VERSION ""

NS_ :

BS_:

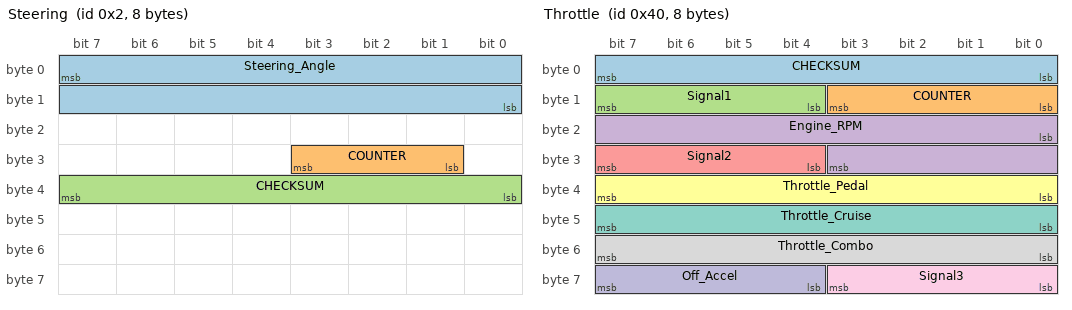
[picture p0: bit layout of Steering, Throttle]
BO_ 2 Steering: 8 XXX
 SG_ Steering_Angle : 7|16@0- (0.1,0) [0|65535] "" XXX
 SG_ COUNTER : 25|3@1+ (1,0) [0|7] "" XXX
 SG_ CHECKSUM : 32|8@1+ (1,0) [0|255] "" XXX

BO_ 64 Throttle: 8 XXX
 SG_ CHECKSUM : 0|8@1+ (1,0) [0|255] "" XXX
 SG_ COUNTER : 8|4@1+ (1,0) [0|15] "" XXX
 SG_ Signal1 : 12|4@1+ (1,0) [0|15] "" XXX
 SG_ Engine_RPM : 16|12@1+ (1,0) [0|4095] "" XXX
 SG_ Signal2 : 28|4@1+ (1,0) [0|15] "" XXX
 SG_ Throttle_Pedal : 32|8@1+ (1,0) [0|255] "" XXX
 SG_ Throttle_Cruise : 40|8@1+ (1,0) [0|255] "" XXX
 SG_ Throttle_Combo : 48|8@1+ (1,0) [0|255] "" XXX
 SG_ Signal3 : 56|4@1+ (1,0) [0|15] "" XXX
 SG_ Off_Accel : 60|4@1+ (1,0) [0|15] "" XXX

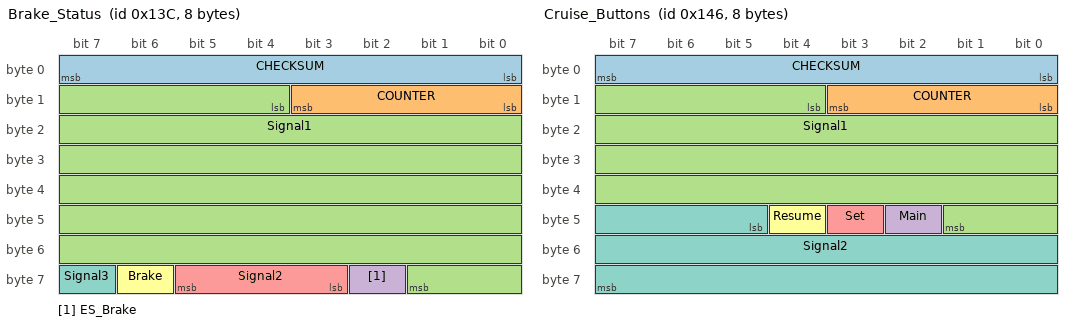
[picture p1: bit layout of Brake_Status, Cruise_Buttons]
BO_ 316 Brake_Status: 8 XXX
 SG_ CHECKSUM : 0|8@1+ (1,0) [0|255] "" XXX
 SG_ COUNTER : 8|4@1+ (1,0) [0|15] "" XXX
 SG_ Signal1 : 12|46@1+ (1,0) [0|1] "" XXX
 SG_ ES_Brake : 58|1@1+ (1,0) [0|1] "" XXX
 SG_ Signal2 : 59|3@1+ (1,0) [0|1] "" XXX
 SG_ Brake : 62|1@1+ (1,0) [0|1] "" XXX
 SG_ Signal3 : 63|1@1+ (1,0) [0|1] "" XXX

BO_ 326 Cruise_Buttons: 8 XXX
 SG_ CHECKSUM : 0|8@1+ (1,0) [0|255] "" XXX
 SG_ COUNTER : 8|4@1+ (1,0) [0|15] "" XXX
 SG_ Signal1 : 12|30@1+ (1,0) [0|1073741823] "" XXX
 SG_ Main : 42|1@1+ (1,0) [0|1] "" XXX
 SG_ Set : 43|1@1+ (1,0) [0|1] "" XXX
 SG_ Resume : 44|1@1+ (1,0) [0|1] "" XXX
 SG_ Signal2 : 45|19@1+ (1,0) [0|524287] "" XXX

BO_ 315 G_Sensor: 8 XXX
 SG_ Lateral : 48|8@1- (-0.1,0) [0|255] "m/s2" XXX
 SG_ Longitudinal : 56|8@1- (-0.1,0) [0|255] "m/s2" XXX

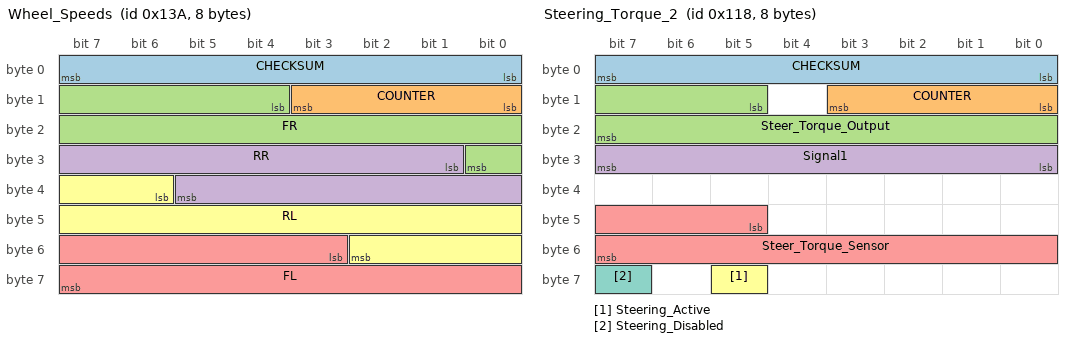
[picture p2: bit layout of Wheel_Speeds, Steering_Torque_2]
BO_ 314 Wheel_Speeds: 8 XXX
 SG_ CHECKSUM : 0|8@1+ (1,0) [0|255] "" XXX
 SG_ COUNTER : 8|4@1+ (1,0) [0|15] "" XXX
 SG_ FR : 12|13@1+ (0.057,0) [0|255] "kph" XXX
 SG_ RR : 25|13@1+ (0.057,0) [0|255] "kph" XXX
 SG_ FL : 51|13@1+ (0.057,0) [0|255] "kph" XXX
 SG_ RL : 38|13@1+ (0.057,0) [0|255] "kph" XXX

BO_ 280 Steering_Torque_2: 8 XXX
 SG_ CHECKSUM : 0|8@1+ (1,0) [0|255] "" XXX
 SG_ COUNTER : 8|4@1+ (1,0) [0|15] "" XXX
 SG_ Steer_Torque_Output : 13|11@1- (-10,0) [0|255] "" XXX
 SG_ Signal1 : 24|8@1+ (1,0) [0|511] "" XXX
 SG_ Steer_Torque_Sensor : 45|11@1- (-1,0) [0|255] "" XXX
 SG_ Steering_Active : 61|1@0+ (1,0) [0|1] "" XXX
 SG_ Steering_Disabled : 63|1@1+ (1,0) [0|1] "" XXX

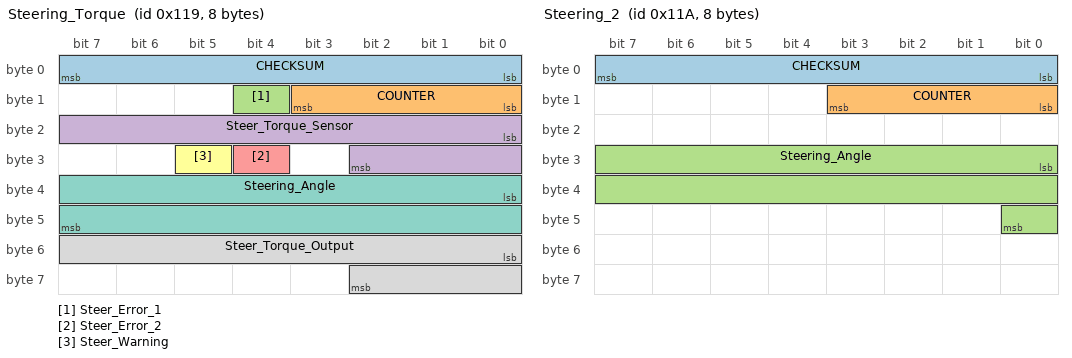
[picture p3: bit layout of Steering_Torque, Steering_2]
BO_ 281 Steering_Torque: 8 XXX
 SG_ CHECKSUM : 0|8@1+ (1,0) [0|255] "" XXX
 SG_ COUNTER : 8|4@1+ (1,0) [0|15] "" XXX
 SG_ Steer_Error_1 : 12|1@0+ (1,0) [0|1] "" XXX
 SG_ Steer_Torque_Sensor : 16|11@1- (-1,0) [-1000|1000] "" XXX
 SG_ Steer_Error_2 : 28|1@1+ (1,0) [0|1] "" XXX
 SG_ Steer_Warning : 29|1@1+ (1,0) [0|1] "" XXX
 SG_ Steering_Angle : 32|16@1- (-0.0217,0) [-600|600] "" X
 SG_ Steer_Torque_Output : 48|11@1- (-10,0) [-1000|1000] "" XXX

BO_ 282 Steering_2: 8 XXX
 SG_ CHECKSUM : 0|8@1+ (1,0) [0|1] "" XXX
 SG_ COUNTER : 8|4@1+ (1,0) [0|1] "" XXX
 SG_ Steering_Angle : 24|17@1- (-0.01,0) [0|1] "" XXX

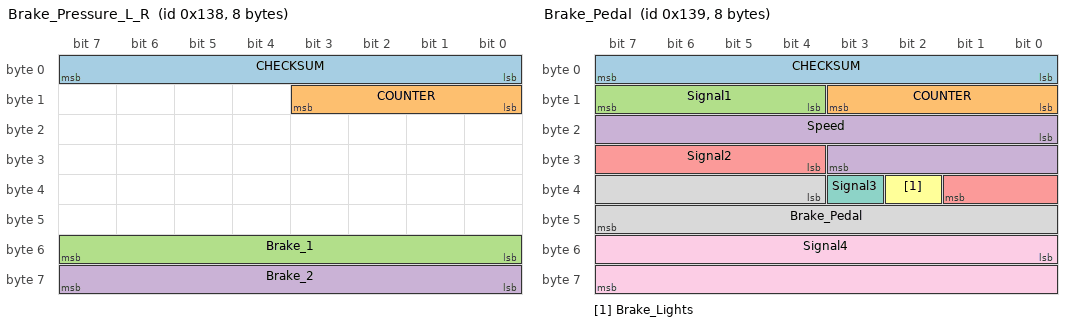
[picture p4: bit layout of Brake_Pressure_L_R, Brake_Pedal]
BO_ 312 Brake_Pressure_L_R: 8 XXX
 SG_ CHECKSUM : 0|8@1+ (1,0) [0|255] "" XXX
 SG_ COUNTER : 8|4@1+ (1,0) [0|15] "" XXX
 SG_ Brake_1 : 48|8@1+ (1,0) [0|255] "" XXX
 SG_ Brake_2 : 56|8@1+ (1,0) [0|255] "" XXX

BO_ 313 Brake_Pedal: 8 XXX
 SG_ CHECKSUM : 0|8@1+ (1,0) [0|255] "" XXX
 SG_ COUNTER : 8|4@1+ (1,0) [0|15] "" XXX
 SG_ Signal1 : 12|4@1+ (1,0) [0|15] "" XXX
 SG_ Speed : 16|12@1+ (0.05625,0) [0|255] "kph" XXX
 SG_ Signal2 : 28|6@1+ (1,0) [0|63] "" XXX
 SG_ Brake_Lights : 34|1@1+ (1,0) [0|1] "" XXX
 SG_ Signal3 : 35|1@1+ (1,0) [0|1] "" XXX
 SG_ Brake_Pedal : 36|12@1+ (1,0) [0|4095] "" XXX
 SG_ Signal4 : 48|16@1+ (1,0) [0|65535] "" XXX

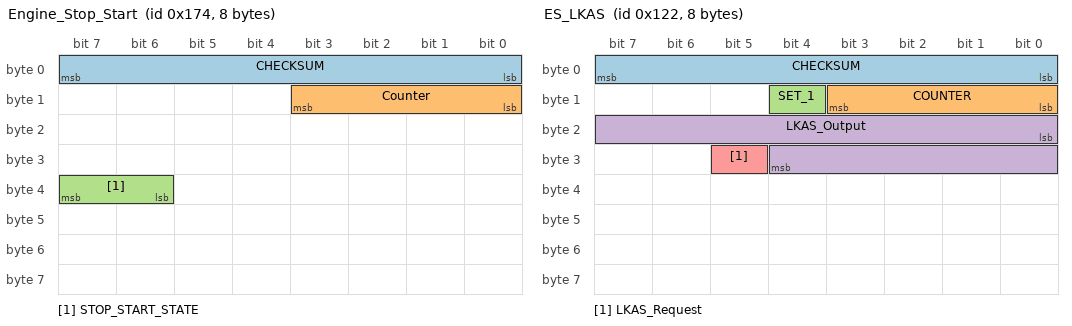
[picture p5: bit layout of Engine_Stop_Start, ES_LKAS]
BO_ 372 Engine_Stop_Start: 8 XXX
 SG_ CHECKSUM : 0|8@1+ (1,0) [0|255] "" XXX
 SG_ Counter : 8|4@1+ (1,0) [0|15] "" XXX
 SG_ STOP_START_STATE : 39|2@0+ (1,0) [0|3] "" XXX

BO_ 290 ES_LKAS: 8 XXX
 SG_ CHECKSUM : 0|8@1+ (1,0) [0|255] "" XXX
 SG_ COUNTER : 8|4@1+ (1,0) [0|15] "" XXX
 SG_ SET_1 : 12|1@0+ (1,0) [0|1] "" XXX
 SG_ LKAS_Output : 16|13@1- (-1,0) [-8191|8191] "" XXX
 SG_ LKAS_Request : 29|1@0+ (1,0) [0|1] "" XXX

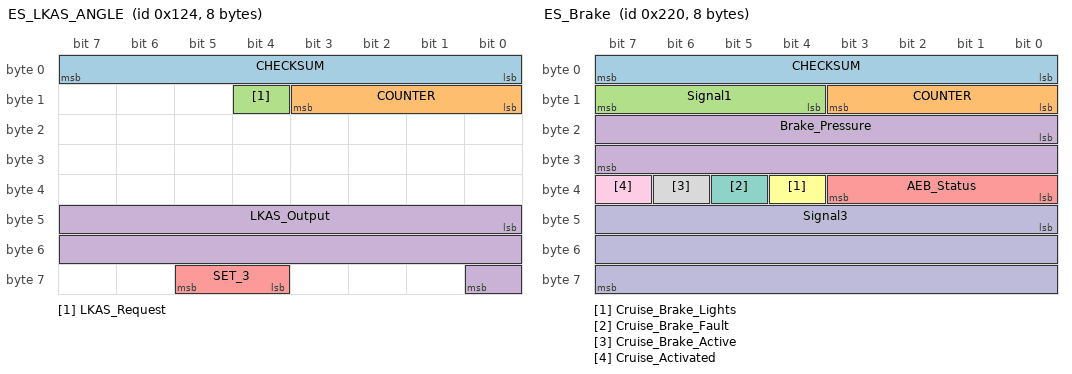
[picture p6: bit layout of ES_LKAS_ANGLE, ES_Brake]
BO_ 292 ES_LKAS_ANGLE: 8 XXX
 SG_ CHECKSUM : 0|8@1+ (1,0) [0|1] "" XXX
 SG_ COUNTER : 8|4@1+ (1,0) [0|1] "" XXX
 SG_ LKAS_Request : 12|1@1+ (1,0) [0|1] "" XXX
 SG_ LKAS_Output : 40|17@1- (-0.01,0) [0|1] "deg" XXX
 SG_ SET_3 : 60|2@1+ (1,0) [0|1] "" XXX

BO_ 544 ES_Brake: 8 XXX
 SG_ CHECKSUM : 0|8@1+ (1,0) [0|255] "" XXX
 SG_ COUNTER : 8|4@1+ (1,0) [0|15] "" XXX
 SG_ Signal1 : 12|4@1+ (1,0) [0|15] "" XXX
 SG_ Brake_Pressure : 16|16@1+ (1,0) [0|65535] "" XXX
 SG_ AEB_Status : 32|4@1+ (1,0) [0|15] "" XXX
 SG_ Cruise_Brake_Lights : 36|1@1+ (1,0) [0|1] "" XXX
 SG_ Cruise_Brake_Fault : 37|1@1+ (1,0) [0|1] "" XXX
 SG_ Cruise_Brake_Active : 38|1@1+ (1,0) [0|1] "" XXX
 SG_ Cruise_Activated : 39|1@1+ (1,0) [0|1] "" XXX
 SG_ Signal3 : 40|24@1+ (1,0) [0|16777215] "" XXX

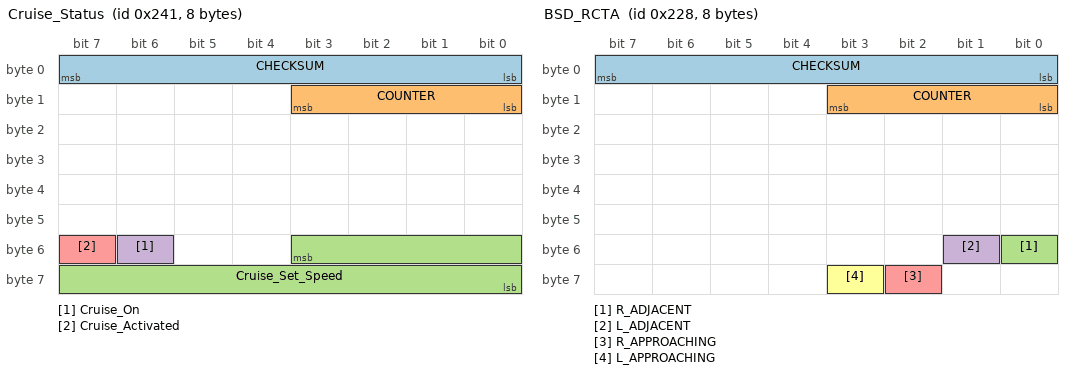
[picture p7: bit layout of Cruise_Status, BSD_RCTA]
BO_ 577 Cruise_Status: 8 XXX
 SG_ CHECKSUM : 0|8@1+ (1,0) [0|255] "" XXX
 SG_ COUNTER : 8|4@1+ (1,0) [0|15] "" XXX
 SG_ Cruise_Set_Speed : 51|12@0+ (1,0) [0|120] "" XXX
 SG_ Cruise_On : 54|1@1+ (1,0) [0|1] "" XXX
 SG_ Cruise_Activated : 55|1@1+ (1,0) [0|1] "" XXX

BO_ 552 BSD_RCTA: 8 XXX
 SG_ CHECKSUM : 0|8@1+ (1,0) [0|255] "" XXX
 SG_ COUNTER : 8|4@1+ (1,0) [0|15] "" XXX
 SG_ R_ADJACENT : 48|1@1+ (1,0) [0|1] "" XXX
 SG_ L_ADJACENT : 49|1@1+ (1,0) [0|1] "" XXX
 SG_ R_APPROACHING : 58|1@1+ (1,0) [0|1] "" XXX
 SG_ L_APPROACHING : 59|1@1+ (1,0) [0|1] "" XXX

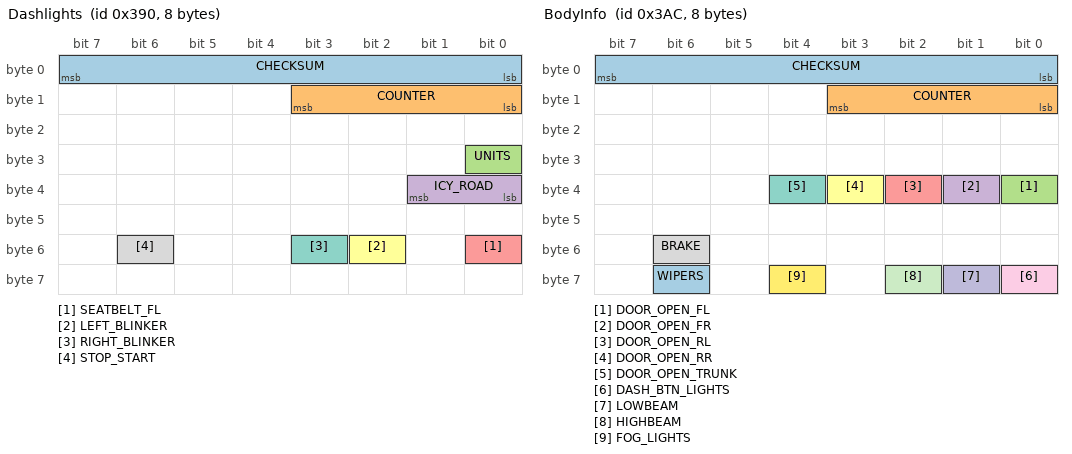
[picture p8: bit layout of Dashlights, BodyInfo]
BO_ 912 Dashlights: 8 XXX
 SG_ CHECKSUM : 0|8@1+ (1,0) [0|255] "" XXX
 SG_ COUNTER : 8|4@1+ (1,0) [0|15] "" XXX
 SG_ UNITS : 24|1@1+ (1,0) [0|1] "" XXX
 SG_ ICY_ROAD : 32|2@1+ (1,0) [0|3] "" XXX
 SG_ SEATBELT_FL : 48|1@1+ (1,0) [0|1] "" XXX
 SG_ LEFT_BLINKER : 50|1@1+ (1,0) [0|1] "" XXX
 SG_ RIGHT_BLINKER : 51|1@1+ (1,0) [0|1] "" XXX
 SG_ STOP_START : 54|1@0+ (1,0) [0|1] "" XXX

BO_ 940 BodyInfo: 8 XXX
 SG_ CHECKSUM : 0|8@1+ (1,0) [0|255] "" XXX
 SG_ COUNTER : 8|4@1+ (1,0) [0|15] "" XXX
 SG_ DOOR_OPEN_FL : 32|1@1+ (1,0) [0|1] "" XXX
 SG_ DOOR_OPEN_FR : 33|1@1+ (1,0) [0|1] "" XXX
 SG_ DOOR_OPEN_RL : 34|1@1+ (1,0) [0|1] "" XXX
 SG_ DOOR_OPEN_RR : 35|1@1+ (1,0) [0|1] "" XXX
 SG_ DOOR_OPEN_TRUNK : 36|1@0+ (1,0) [0|1] "" XXX
 SG_ BRAKE : 54|1@1+ (1,0) [0|1] "" XXX
 SG_ DASH_BTN_LIGHTS : 56|1@0+ (1,0) [0|1] "" XXX
 SG_ LOWBEAM : 57|1@1+ (1,0) [0|1] "" XXX
 SG_ HIGHBEAM : 58|1@1+ (1,0) [0|1] "" XXX
 SG_ FOG_LIGHTS : 60|1@1+ (1,0) [0|1] "" XXX
 SG_ WIPERS : 62|1@0+ (1,0) [0|1] "" XXX

BO_ 801 ES_DashStatus: 8 XXX
 SG_ CHECKSUM : 0|8@1+ (1,0) [0|255] "" XXX
 SG_ COUNTER : 8|4@1+ (1,0) [0|15] "" XXX
 SG_ PCB_Off : 12|1@1+ (1,0) [0|1] "" XXX
 SG_ LDW_Off : 13|1@1+ (1,0) [0|1] "" XXX
 SG_ Signal1 : 14|2@1+ (1,0) [0|3] "" XXX
 SG_ Cruise_State_Msg : 16|4@1+ (1,0) [0|15] "" XXX
 SG_ LKAS_State_Msg : 20|3@1+ (1,0) [0|7] "" XXX
 SG_ Signal2 : 23|1@1+ (1,0) [0|1] "" XXX
 SG_ Cruise_Soft_Disable : 24|1@1+ (1,0) [0|1] "" XXX
 SG_ Cruise_Status_Msg : 25|2@1+ (1,0) [0|3] "" XXX
 SG_ Signal3 : 27|1@1+ (1,0) [0|1] "" XXX
 SG_ Cruise_Distance : 28|3@1+ (1,0) [0|7] "" XXX
 SG_ Signal4 : 31|1@1+ (1,0) [0|1] "" XXX
 SG_ Conventional_Cruise : 32|1@1+ (1,0) [0|1] "" XXX
 SG_ Signal5 : 33|2@1+ (1,0) [0|3] "" XXX
 SG_ Cruise_Disengaged : 35|1@1+ (1,0) [0|1] "" XXX
 SG_ Cruise_Activated : 36|1@1+ (1,0) [0|1] "" XXX
 SG_ Signal6 : 37|3@1+ (1,0) [0|1] "" XXX
 SG_ Cruise_Set_Speed : 40|8@1+ (1,0) [0|255] "" XXX
 SG_ Cruise_Fault : 48|1@1+ (1,0) [0|1] "" XXX
 SG_ Cruise_On : 49|1@1+ (1,0) [0|1] "" XXX
 SG_ Display_Own_Car : 50|1@1+ (1,0) [0|1] "" XXX
 SG_ Brake_Lights : 51|1@1+ (1,0) [0|1] "" XXX
 SG_ Car_Follow : 52|1@1+ (1,0) [0|1] "" XXX
 SG_ Signal7 : 53|3@1+ (1,0) [0|1] "" XXX
 SG_ Far_Distance : 56|4@1+ (5,0) [0|75] "m" XXX
 SG_ Cruise_State : 60|4@1+ (1,0) [0|15] "" XXX

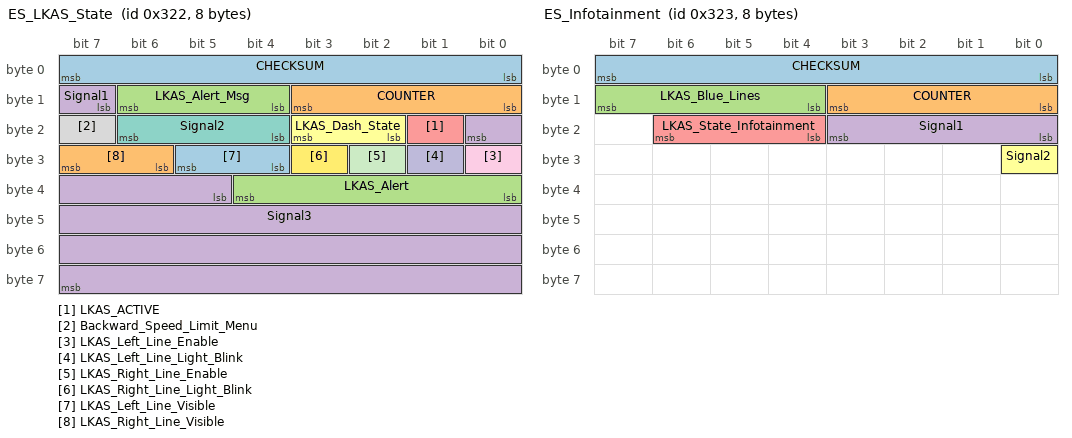
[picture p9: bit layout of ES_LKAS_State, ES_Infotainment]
BO_ 802 ES_LKAS_State: 8 XXX
 SG_ CHECKSUM : 0|8@1+ (1,0) [0|255] "" XXX
 SG_ COUNTER : 8|4@1+ (1,0) [0|15] "" XXX
 SG_ LKAS_Alert_Msg : 12|3@1+ (1,0) [0|7] "" XXX
 SG_ Signal1 : 15|2@1+ (1,0) [0|3] "" XXX
 SG_ LKAS_ACTIVE : 17|1@1+ (1,0) [0|1] "" XXX
 SG_ LKAS_Dash_State : 18|2@1+ (1,0) [0|2] "" XXX
 SG_ Signal2 : 20|3@1+ (1,0) [0|7] "" XXX
 SG_ Backward_Speed_Limit_Menu : 23|1@1+ (1,0) [0|1] "" XXX
 SG_ LKAS_Left_Line_Enable : 24|1@1+ (1,0) [0|1] "" XXX
 SG_ LKAS_Left_Line_Light_Blink : 25|1@1+ (1,0) [0|1] "" XXX
 SG_ LKAS_Right_Line_Enable : 26|1@1+ (1,0) [0|1] "" XXX
 SG_ LKAS_Right_Line_Light_Blink : 27|1@1+ (1,0) [0|1] "" XXX
 SG_ LKAS_Left_Line_Visible : 28|2@1+ (1,0) [0|3] "" XXX
 SG_ LKAS_Right_Line_Visible : 30|2@1+ (1,0) [0|3] "" XXX
 SG_ LKAS_Alert : 32|5@1+ (1,0) [0|31] "" XXX
 SG_ Signal3 : 37|27@1+ (1,0) [0|1] "" XXX

BO_ 803 ES_Infotainment: 8 XXX
 SG_ CHECKSUM : 0|8@1+ (1,0) [0|255] "" XXX
 SG_ COUNTER : 8|4@1+ (1,0) [0|15] "" XXX
 SG_ LKAS_Blue_Lines : 15|4@0+ (1,0) [0|15] "" XXX
 SG_ Signal1 : 19|4@0+ (1,0) [0|15] "" XXX
 SG_ LKAS_State_Infotainment : 22|3@0+ (1,0) [0|7] "" XXX
 SG_ Signal2 : 24|1@0+ (1,0) [0|1] "" XXX

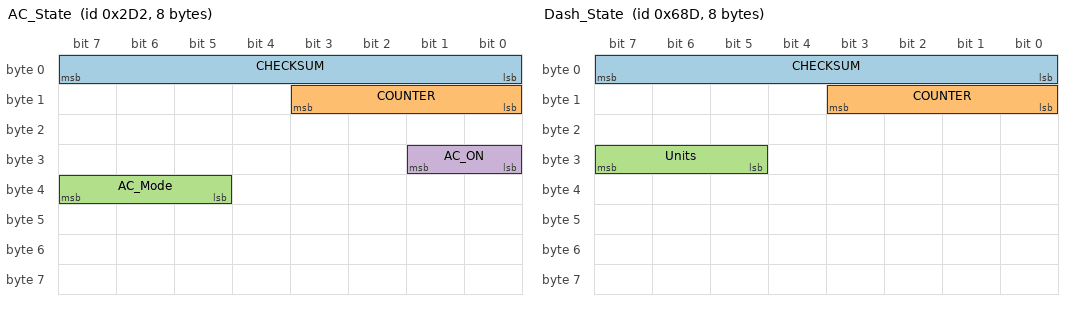
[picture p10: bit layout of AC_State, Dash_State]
BO_ 722 AC_State: 8 XXX
 SG_ CHECKSUM : 0|8@1+ (1,0) [0|255] "" XXX
 SG_ COUNTER : 8|4@1+ (1,0) [0|15] "" XXX
 SG_ AC_Mode : 37|3@1+ (1,0) [0|1] "" XXX
 SG_ AC_ON : 24|2@1+ (1,0) [0|1] "" XXX

BO_ 1677 Dash_State: 8 XXX
 SG_ CHECKSUM : 0|8@1+ (1,0) [0|255] "" XXX
 SG_ COUNTER : 8|4@1+ (1,0) [0|15] "" XXX
 SG_ Units : 29|3@1+ (1,0) [0|7] "" XXX

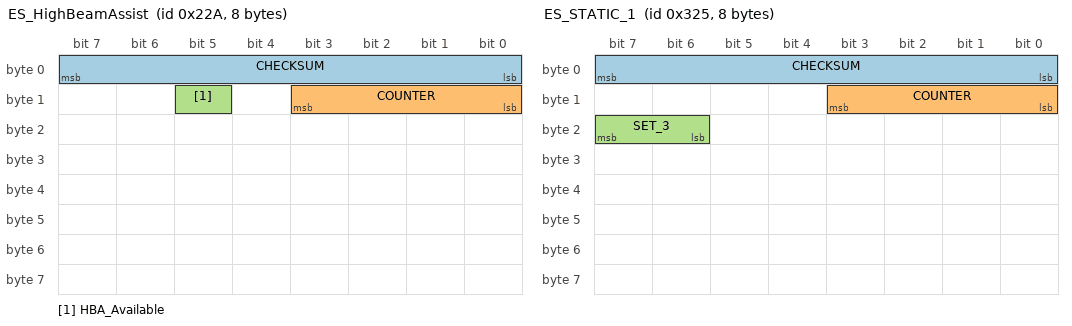
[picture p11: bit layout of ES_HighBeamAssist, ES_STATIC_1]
BO_ 554 ES_HighBeamAssist: 8 XXX
 SG_ CHECKSUM : 0|8@1+ (1,0) [0|255] "" XXX
 SG_ COUNTER : 8|4@1+ (1,0) [0|15] "" XXX
 SG_ HBA_Available : 13|1@0+ (1,0) [0|1] "" XXX

BO_ 805 ES_STATIC_1: 8 XXX
 SG_ CHECKSUM : 0|8@1+ (1,0) [0|255] "" XXX
 SG_ COUNTER : 8|4@1+ (1,0) [0|15] "" XXX
 SG_ SET_3 : 23|2@0+ (1,0) [0|3] "" XXX

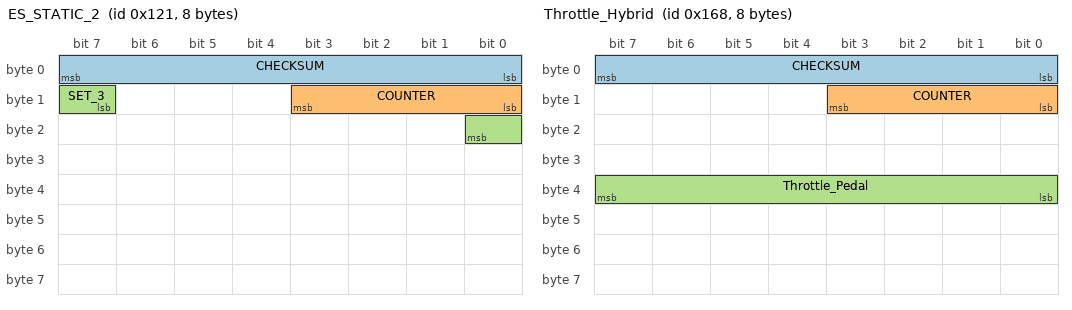
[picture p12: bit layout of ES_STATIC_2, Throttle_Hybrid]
BO_ 289 ES_STATIC_2: 8 XXX
 SG_ CHECKSUM : 0|8@1+ (1,0) [0|255] "" XXX
 SG_ COUNTER : 8|4@1+ (1,0) [0|15] "" XXX
 SG_ SET_3 : 15|2@1+ (1,0) [0|3] "" XXX

BO_ 39 Cruise_Status_2: 8 XXX
 SG_ Cruise_Activated : 37|1@0+ (1,0) [0|1] "" XXX

BO_ 295 Transmission: 8 XXX
 SG_ Gear : 44|4@1+ (1,0) [0|15] "" XXX

BO_ 360 Throttle_Hybrid: 8 XXX
 SG_ CHECKSUM : 0|8@1+ (1,0) [0|255] "" XXX
 SG_ COUNTER : 8|4@1+ (1,0) [0|15] "" XXX
 SG_ Throttle_Pedal : 32|8@1+ (1,0) [0|255] "" XXX

BO_ 550 Brake_Hybrid: 8 XXX
 SG_ Brake_Pedal : 24|8@1+ (1,0) [0|1] "" XXX
 SG_ Brake : 37|1@1+ (1,0) [0|1] "" XXX

BU_: CLOCK HUD H_U DATC CCP KMA_TMU CUBIS TMU IPM RSE_R RRC CGW RSE_L AMP EDT SWRC IBOX CLU FHCU ASD MON AVM KBD

CM_ "AUTOGENERATED FILE, DO NOT EDIT";

CM_ "Imported file _honda_common.dbc starts here";
CM_ SG_ 304 "Seems to be platform-agnostic";
CM_ SG_ 316 "Should exist on Nidec";
CM_ SG_ 420 BRAKE_HOLD_RELATED "On when Brake Hold engaged";
CM_ SG_ 490 LONG_ACCEL "wheel speed derivative, noisy and zero snapping";
CM_ SG_ 773 PASS_AIRBAG_ON "Might just be indicator light";
CM_ SG_ 773 PASS_AIRBAG_OFF "Might just be indicator light";
CM_ SG_ 780 CRUISE_SPEED "255 = no speed";
CM_ SG_ 780 PCM_SPEED "Used by Nidec";
CM_ SG_ 780 PCM_GAS "Used by Nidec";
CM_ SG_ 804 CRUISE_SPEED_PCM "255 = no speed";

CM_ "Imported file _bosch_2018.dbc starts here";
CM_ SG_ 450 EPB_STATE "3: On, 2: Disengaging, 1: Engaging, 0: Off";
CM_ SG_ 576 LINE_DISTANCE_VISIBLE "Length of line visible, undecoded";
CM_ SG_ 577 LINE_FAR_EDGE_POSITION "Appears to be a measure of line thickness, indicates location of the portion of the line furthest from the car, undecoded";
CM_ SG_ 577 LINE_PARAMETER "Unclear if this is low quality line curvature rate or if this is something else, but it is correlated with line curvature, undecoded";
CM_ SG_ 577 LINE_DASHED "1 = line is dashed";
CM_ SG_ 577 LINE_SOLID "1 = line is solid";

CM_ "Imported file _bosch_adas_2018.dbc starts here";
CM_ SG_ 479 CONTROL_ON "Set to 5 when car is being controlled";
CM_ SG_ 479 AEB_STATUS "set for the duration of AEB event";
CM_ SG_ 479 AEB_BRAKING "set when braking is commanded during AEB event";
CM_ SG_ 479 AEB_PREPARE "set 1s before AEB";
CM_ SG_ 829 BEEP "beeps are pleasant, chimes are for warnngs etc...";

CM_ "Imported file _steering_sensors_a.dbc starts here";
CM_ "honda_accord_2018_can.dbc starts here";

VAL_ 513 STATE 5 "FAULT_TIMEOUT" 4 "FAULT_STARTUP" 3 "FAULT_SCE" 2 "FAULT_SEND" 1 "FAULT_BAD_CHECKSUM" 0 "NO_FAULT" ;

VAL_ 295 GEAR 0 "P" 1 "R" 2 "N" 3 "D" 4 "B";
VAL_ 466 CRUISE_STATE 11 "timer_3sec" 10 "adaptive click down" 9 "adaptive click up" 8 "adaptive engaged" 7 "standstill" 6 "non-adaptive click up" 5 "non-adaptive click down" 4 "non-adaptive hold down" 3 "non-adaptive hold up" 2 "non-adaptive being engaged" 1 "non-adaptive engaged" 0 "off";
VAL_ 467 LOW_SPEED_LOCKOUT 2 "low speed locked" 1 "ok";
VAL_ 467 PCM_FOLLOW_DISTANCE 1 "far" 2 "medium" 3 "close";
VAL_ 614 STATE 3 "enabled" 1 "disabled";
VAL_ 614 DIRECTION_CMD 3 "right" 2 "center" 1 "left";
VAL_ 643 STATE 0 "normal" 1 "adaptive_cruise_control" 3 "emergency_braking";
VAL_ 835 ACC_TYPE 2 "permanent low speed lockout" 1 "ok";
VAL_ 835 ACC_MALFUNCTION 1 "faulted" 0 "ok";
VAL_ 835 ACC_CUT_IN 1 "CUT-IN Detected" 0 "clear";
VAL_ 835 ALLOW_LONG_PRESS 2 "set speed increase by 5 speed units regardless" 1 "set speed increase by 1 speed unit on short press, 5 speed units on long press";
VAL_ 865 CLUTCH_RELEASED 0 "clutch pressed any amount" 1 "clutch released"
VAL_ 921 CRUISE_CONTROL_STATE 2 "disabled" 11 "hold" 10 "hold_waiting_user_cmd" 6 "enabled" 5 "faulted";
VAL_ 956 SPORT_ON 0 "off" 1 "on";
VAL_ 956 GEAR 0 "D" 1 "S" 8 "N" 16 "R" 32 "P";
VAL_ 956 SPORT_GEAR_ON 0 "off" 1 "on";
VAL_ 956 SPORT_GEAR 1 "S1" 2 "S2" 3 "S3" 4 "S4" 5 "S5" 6 "S6";
VAL_ 956 ECON_ON 0 "off" 1 "on";
VAL_ 956 B_GEAR_ENGAGED 0 "off" 1 "on";
VAL_ 956 DRIVE_ENGAGED 0 "off" 1 "on";
VAL_ 1005 REVERSE_CAMERA_GUIDELINES 3 "No guidelines" 2 "Static guidelines" 1 "Active guidelines";
VAL_ 1009 PCM_FOLLOW_DISTANCE 1 "far" 2 "medium" 3 "close";
VAL_ 1041 PCS_INDICATOR 2 "PCS Faulted" 1 "PCS Turned Off By User" 0 "PCS Enabled";
VAL_ 1041 PCS_SENSITIVITY 64 "high sensitivity"  128 "mid sensitivity" 192 "low sensitivity" 0 "off";
VAL_ 1042 LDA_ALERT 3 "hold with continuous beep" 2 "LDA unavailable" 1 "hold" 0 "none";
VAL_ 1042 BARRIERS 3 "left" 2 "right" 1 "both" 0 "none";
VAL_ 1042 RIGHT_LINE 3 "orange" 2 "faded" 1 "solid" 0 "none";
VAL_ 1042 LKAS_STATUS 1 "on" 0 "off";
VAL_ 1042 LEFT_LINE 3 "orange" 2 "faded" 1 "solid" 0 "none";
VAL_ 1042 LDA_ON_MESSAGE 2 "Lane Departure Alert Turned ON, Steering Assist Inactive" 1 "Lane Departure Alert Turned ON, Steering Assist Active" 0 "clear";
VAL_ 1042 LDA_SA_TOGGLE  2 "steering assist off" 1 "steering assist on";
VAL_ 1042 LDA_SENSITIVITY 2 "standard" 1 "high" 0 "undefined";
VAL_ 1042 LDA_MESSAGES 4 "lda unavailable at this speed" 1 "lda unavailable below approx 50km/h" 0 "ok";
VAL_ 1042 LDA_FRONT_CAMERA_BLOCKED 1 "lda unavailable" 0 "ok";
VAL_ 1042 TAKE_CONTROL 1 "take control" 0 "ok";
VAL_ 1042 LANE_SWAY_WARNING 3 "ok" 2 "orange please take a break" 1 "prompt would you like to take a break" 0 "ok";
VAL_ 1042 LANE_SWAY_BUZZER 3 "ok" 2 "beep twice" 1 "beep twice" 0 "ok";
VAL_ 1161 TSGN1 1 "speed sign" 0 "none";
VAL_ 1161 TSGN2 1 "speed sign" 0 "none";
VAL_ 1161 SPLSGN2 15 "conditional blank" 4 "wet road" 5 "rain" 0 "none";
VAL_ 1162 TSGN3 0 "none" 1 "speed sign" 2 "0 unlimited" 7 "unlimited" 16 "highway" 17 "no highway" 18 "motorway" 19 "no motorway" 20 "in city" 21 "outside city" 22 "pedestrian area" 23 "no pedestrian area" 65 "no overtaking left" 66 "no overtaking right" 67 "overtaking allowed again" 81 "no right turn" 97 "stop" 105 "yield" 113 "stop" 114 "yield us" 129 "no entry" 138 "no entry tss2" 145 "do not enter";
VAL_ 1162 SPLSGN3 15 "conditional blank" 4 "wet road" 5 "rain" 0 "none";
VAL_ 1552 METER_SLIDER_LOW_BRIGHTNESS 1 "Low brightness mode, footwell lights off" 0 "Normal mode, footwell lights on";
VAL_ 1552 METER_SLIDER_DIMMED 1 "Dimmed" 0 "Not Dimmed";
VAL_ 1552 UNITS 1 "km (km/L)" 2 "km (L/100km)" 3 "miles (MPG US)" 4 "miles (MPG Imperial)";
VAL_ 1553 UNITS 1 "km" 2 "miles";
VAL_ 1556 TURN_SIGNALS 3 "none" 2 "right" 1 "left";
VAL_ 1592 LOCK_STATUS 0 "locked" 1 "unlocked";

VAL_ 401 SETME_X3 3 "TSS 2.0" 1 "TSS 2.5 or 2022 RAV4" 0 "TSS 2.0 on Alphard, Highlander, NX";
VAL_ 610 IPAS_STATE 5 "override" 3 "enabled" 1 "disabled";
VAL_ 610 LKA_STATE 25 "temporary_fault" 17 "permanent_fault" 11 "lka_missing_unavailable2" 9 "temporary_fault2" 5 "active" 3 "lka_missing_unavailable" 1 "standby";
